# MU3E_SC_HUB register map
Vendor: Mu3e; Series: MU3E_FPGA_IP; File version: 26.6.9.0414
CMSIS-SVD description of the slow-control hub internal CSR window. BaseAddress is 0 because this file describes the relative hub-owned register window; system integration supplies the live slave base address.
Registers are 32-bit, read-only, reset 0x0 unless marked. A register's access mark holds for its fields unless they carry their own. Offsets are from the block's base; lines under a group give offsets from that group; [hi:lo] are bit positions; {n}, {i} and the like mark numbered series; 'fields as' and 'values as' point back to an identical list; <NAME> marks a mode.

## Memory map
0x00000000 SC_HUB_INTERNAL_CSR size 0x80 — Relative internal CSR aperture for the slow-control hub. The window spans 32 words; registers not listed in this file are reserved holes.

## SC_HUB_INTERNAL_CSR — Relative internal CSR aperture for the slow-control hub. The window spans 32 words; registers not listed in this file are reserved holes.
Base 0x00000000
0x00 UID reset 0x53434842 — Immutable Mu3e IP identifier. Default ASCII "SCHB".
  [31:0] value — Compile-time or integration-time UID word. Default ASCII "SCHB".
0x04 META rw — Read-multiplexed metadata word. Write page_sel[1:0] before reading back: 0=VERSION, 1=DATE, 2=GIT, 3=INSTANCE_ID.
  [1:0] page_sel — Selects the META readback page.
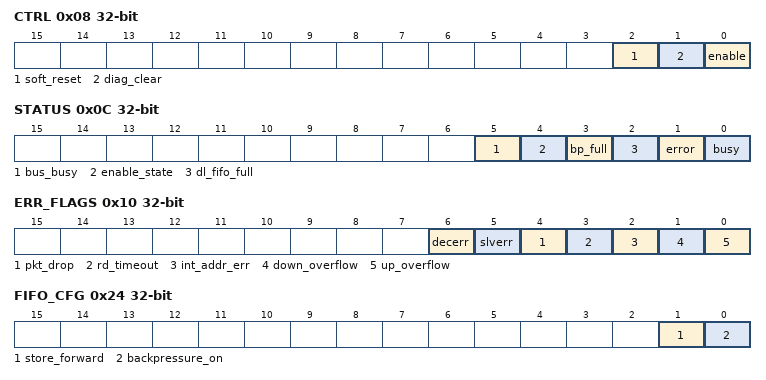
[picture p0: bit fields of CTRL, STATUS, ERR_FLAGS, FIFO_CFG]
0x08 CTRL rw — Enable, diagnostic clear, and software-reset control word.
  [2] soft_reset write-1-sets — Requests a local soft-reset pulse.
  [1] diag_clear write-1-clears — Clears software-visible counters and sticky diagnostics.
  [0] enable — Global enable for packet execution.
0x0C STATUS — Busy/error summary and FIFO/bus state.
  [5] bus_busy — External bus handler is busy.
  [4] enable_state — Current latched enable state.
  [3] bp_full — Reply/backpressure FIFO full.
  [2] dl_fifo_full — Download FIFO full.
  [1] error — Error summary derived from ERR_FLAGS.
  [0] busy — Core FSM is not idle.
0x10 ERR_FLAGS rw — Sticky overflow, timeout, packet-drop, and bus error flags.
  [6] decerr write-1-clears — Decode error returned by the external bus.
  [5] slverr write-1-clears — Slave error returned by the external bus.
  [4] pkt_drop write-1-clears — Malformed or truncated packet was dropped before execution.
  [3] rd_timeout write-1-clears — External read timed out.
  [2] int_addr_err write-1-clears — Internal CSR access targeted an unmapped word.
  [1] down_overflow write-1-clears — Download ingress FIFO overflow observed.
  [0] up_overflow write-1-clears — Upload/backpressure FIFO overflow observed.
0x14 ERR_COUNT — Saturating 32-bit error counter.
  [31:0] value — Accumulated error count.
0x18 SCRATCH rw — General-purpose software scratch register.
  [31:0] value — Scratch value.
0x1C GTS_SNAP_LO — Global-timestamp snapshot low word.
  [31:0] value — Low 32 bits of the captured timestamp.
0x20 GTS_SNAP_HI — Global-timestamp snapshot high word. Reading this register captures a fresh snapshot.
  [31:0] value — High 32 bits of the captured timestamp.
0x24 FIFO_CFG — Backpressure and store-and-forward configuration summary.
  [1] store_forward — Write packets are validated before any external side effect.
  [0] backpressure_on — Reply FIFO/backpressure path present in this build.
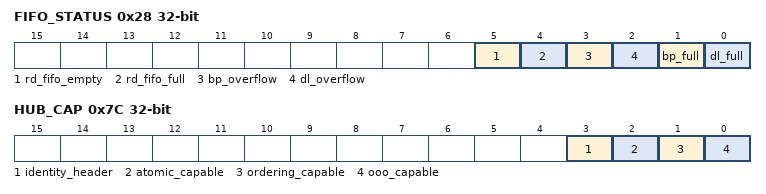
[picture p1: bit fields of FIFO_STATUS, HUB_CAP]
0x28 FIFO_STATUS — Download, reply, and read-data FIFO state summary.
  [5] rd_fifo_empty — Read-data staging FIFO empty.
  [4] rd_fifo_full — Read-data staging FIFO full.
  [3] bp_overflow — Reply/backpressure FIFO overflow sticky summary.
  [2] dl_overflow — Download FIFO overflow sticky summary.
  [1] bp_full — Reply/backpressure FIFO full.
  [0] dl_full — Download FIFO full.
0x2C DOWN_PKT_CNT — Download packet occupancy summary bit.
  [31:0] value — Raw download packet occupancy summary word.
0x30 UP_PKT_CNT — Reply FIFO packet count.
  [31:0] value
0x34 DOWN_USEDW — Download FIFO used words.
  [31:0] value — Download FIFO occupancy in words.
0x38 UP_USEDW — Reply FIFO used words.
  [31:0] value — Reply FIFO occupancy in words.
0x3C EXT_PKT_RD — External read packet counter.
  [31:0] value — Count of external read packets.
0x40 EXT_PKT_WR — External write packet counter.
  [31:0] value — Count of external write packets.
0x44 EXT_WORD_RD — External read word counter.
  [31:0] value — Count of external read data words.
0x48 EXT_WORD_WR — External write word counter.
  [31:0] value — Count of external write data words.
0x4C LAST_RD_ADDR — Last external read address.
  [31:0] value — Most recent external read address word.
0x50 LAST_RD_DATA — Last external read data.
  [31:0] value — Most recent external read data word.
0x54 LAST_WR_ADDR — Last external write address.
  [31:0] value — Most recent external write address word.
0x58 LAST_WR_DATA — Last external write data.
  [31:0] value — Most recent external write data word.
0x5C PKT_DROP_CNT — Malformed-packet drop counter.
  [31:0] value — Count of dropped malformed packets.
0x60 OOO_CTRL rw — Runtime out-of-order enable request. Only effective when OOO support is synthesized.
  [0] ooo_runtime_enable — Runtime request to enable out-of-order completion.
0x64 ORD_DRAIN_CNT — Release-drain event counter.
  [31:0] value — Count of release-drain events.
0x68 ORD_HOLD_CNT — Acquire-hold event counter.
  [31:0] value — Count of acquire-hold events.
0x6C DBG_DROP_DETAIL — Last dropped-packet debug detail word.
  [31:0] value — Raw debug detail for the last packet drop.
0x70 FEB_TYPE rw — Local detector-class selector used by M/S/T packet masking: 0=ALL, 1=MUPIX, 2=SCIFI, 3=TILE.
  [1:0] feb_type — Local detector class selector.
0x7C HUB_CAP — Compile-time capability bits and identity-header presence.
  [3] identity_header — Common Mu3e UID + META identity header implemented at words 0x00 and 0x01.
  [2] atomic_capable — Compile-time atomic read-modify-write support synthesized.
  [1] ordering_capable — Compile-time acquire/release ordering tracker synthesized.
  [0] ooo_capable — Compile-time out-of-order support synthesized.
